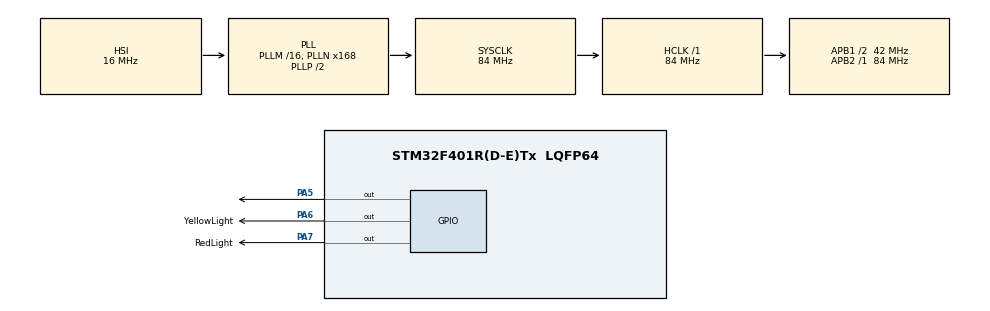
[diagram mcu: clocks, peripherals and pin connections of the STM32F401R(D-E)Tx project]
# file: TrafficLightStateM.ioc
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FREERTOS.Tasks01=vTrafficTask,24,256,StartTrafficTask,Default,NULL,Dynamic,NULL,NULL
Mcu.Family=STM32F4
Mcu.Name=STM32F401R(D-E)Tx
Mcu.Package=LQFP64
NVIC.PriorityGroup=NVIC_PRIORITYGROUP_4
NVIC.TIM5_IRQn=true\:15\:0\:false\:false\:true\:false\:false\:true\:true
NVIC.TimeBase=TIM5_IRQn
NVIC.TimeBaseIP=TIM5
PA5.Signal=GPIO_Output
PA6.GPIO_Label=YellowLight
PA6.Signal=GPIO_Output
PA7.GPIO_Label=RedLight
PA7.Signal=GPIO_Output
ProjectManager.HeapSize=0x200
ProjectManager.StackSize=0x400
ProjectManager.TargetToolchain=STM32CubeIDE
RCC.48MHZClocksFreq_Value=42000000
RCC.AHBFreq_Value=84000000
RCC.APB1CLKDivider=RCC_HCLK_DIV2
RCC.APB1Freq_Value=42000000
RCC.APB1TimFreq_Value=84000000
RCC.APB2Freq_Value=84000000
RCC.APB2TimFreq_Value=84000000
RCC.CortexFreq_Value=84000000
RCC.HCLKFreq_Value=84000000
RCC.HSE_VALUE=25000000
RCC.HSI_VALUE=16000000
RCC.LSE_VALUE=32768
RCC.PLLN=168
RCC.SYSCLKFreq_VALUE=84000000
RCC.SYSCLKSource=RCC_SYSCLKSOURCE_PLLCLK
RCC.VCOOutputFreq_Value=168000000
VP_FREERTOS_VS_CMSIS_V2.Mode=CMSIS_V2
VP_SYS_VS_tim5.Mode=TIM5
board=custom

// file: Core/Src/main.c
/* USER CODE BEGIN Header */
/**
  ******************************************************************************
  * @file           : main.c
  * @brief          : Main program body
  ******************************************************************************
  * @attention
  *
  * Copyright (c) 2026 STMicroelectronics.
  * All rights reserved.
  *
  * This software is licensed under terms that can be found in the LICENSE file
  * in the root directory of this software component.
  * If no LICENSE file comes with this software, it is provided AS-IS.
  *
  ******************************************************************************
  */
/* USER CODE END Header */
#include "main.h"
#include "cmsis_os.h"

/* Definitions for vTrafficTask */
osThreadId_t vTrafficTaskHandle;
const osThreadAttr_t vTrafficTask_attributes = {
  .name = "vTrafficTask",
  .stack_size = 256 * 4,
  .priority = (osPriority_t) osPriorityNormal,
};
/* USER CODE BEGIN PV */
typedef enum
{
	STATE_GREEN,
	STATE_YELLOW,
	STATE_RED
}TrafficState_t;
/* USER CODE END PV */

void SystemClock_Config(void);
static void MX_GPIO_Init(void);
void StartTrafficTask(void *argument);

int main(void)
{

  /* MCU Configuration--------------------------------------------------------*/

  /* Reset of all peripherals, Initializes the Flash interface and the Systick. */
  HAL_Init();

  /* Configure the system clock */
  SystemClock_Config();

  /* Initialize all configured peripherals */
  MX_GPIO_Init();

  /* Init scheduler */
  osKernelInitialize();

  /* Create the thread(s) */
  /* creation of vTrafficTask */
  vTrafficTaskHandle = osThreadNew(StartTrafficTask, NULL, &vTrafficTask_attributes);

  /* Start scheduler */
  osKernelStart();

  /* We should never get here as control is now taken by the scheduler */

  /* Infinite loop */
  while (1)
  {

  }
}

void SystemClock_Config(void)
{
  RCC_OscInitTypeDef RCC_OscInitStruct = {0};
  RCC_ClkInitTypeDef RCC_ClkInitStruct = {0};

  /** Configure the main internal regulator output voltage
  */
  __HAL_RCC_PWR_CLK_ENABLE();
  __HAL_PWR_VOLTAGESCALING_CONFIG(PWR_REGULATOR_VOLTAGE_SCALE2);

  /** Initializes the RCC Oscillators according to the specified parameters
  * in the RCC_OscInitTypeDef structure.
  */
  RCC_OscInitStruct.OscillatorType = RCC_OSCILLATORTYPE_HSI;
  RCC_OscInitStruct.HSIState = RCC_HSI_ON;
  RCC_OscInitStruct.HSICalibrationValue = RCC_HSICALIBRATION_DEFAULT;
  RCC_OscInitStruct.PLL.PLLState = RCC_PLL_ON;
  RCC_OscInitStruct.PLL.PLLSource = RCC_PLLSOURCE_HSI;
  RCC_OscInitStruct.PLL.PLLM = 16;
  RCC_OscInitStruct.PLL.PLLN = 168;
  RCC_OscInitStruct.PLL.PLLP = RCC_PLLP_DIV2;
  RCC_OscInitStruct.PLL.PLLQ = 4;
  if (HAL_RCC_OscConfig(&RCC_OscInitStruct) != HAL_OK)
  {
    Error_Handler();
  }

  /** Initializes the CPU, AHB and APB buses clocks
  */
  RCC_ClkInitStruct.ClockType = RCC_CLOCKTYPE_HCLK|RCC_CLOCKTYPE_SYSCLK
                              |RCC_CLOCKTYPE_PCLK1|RCC_CLOCKTYPE_PCLK2;
  RCC_ClkInitStruct.SYSCLKSource = RCC_SYSCLKSOURCE_PLLCLK;
  RCC_ClkInitStruct.AHBCLKDivider = RCC_SYSCLK_DIV1;
  RCC_ClkInitStruct.APB1CLKDivider = RCC_HCLK_DIV2;
  RCC_ClkInitStruct.APB2CLKDivider = RCC_HCLK_DIV1;

  if (HAL_RCC_ClockConfig(&RCC_ClkInitStruct, FLASH_LATENCY_2) != HAL_OK)
  {
    Error_Handler();
  }
}

static void MX_GPIO_Init(void)
{
  GPIO_InitTypeDef GPIO_InitStruct = {0};

  /* GPIO Ports Clock Enable */
  __HAL_RCC_GPIOA_CLK_ENABLE();

  /*Configure GPIO pin Output Level */
  HAL_GPIO_WritePin(GPIOA, GPIO_PIN_5|YellowLight_Pin|RedLight_Pin, GPIO_PIN_RESET);

  /*Configure GPIO pins : PA5 YellowLight_Pin RedLight_Pin */
  GPIO_InitStruct.Pin = GPIO_PIN_5|YellowLight_Pin|RedLight_Pin;
  GPIO_InitStruct.Mode = GPIO_MODE_OUTPUT_PP;
  GPIO_InitStruct.Pull = GPIO_NOPULL;
  GPIO_InitStruct.Speed = GPIO_SPEED_FREQ_LOW;
  HAL_GPIO_Init(GPIOA, &GPIO_InitStruct);

}

void StartTrafficTask(void *argument)
{
  /* USER CODE BEGIN 5 */
	TrafficState_t currentState = STATE_GREEN;
	//TickType_t startTick;
  /* Infinite loop */
  for(;;)
  {
    //osDelay(1);
	  //startTick = xTaskGetTickCount();
	  switch(currentState)
	  {
	  case STATE_GREEN:
		  HAL_GPIO_WritePin(GPIOA, GPIO_PIN_5, GPIO_PIN_SET);
		  HAL_GPIO_WritePin(GPIOA, GPIO_PIN_6, GPIO_PIN_RESET);
		  HAL_GPIO_WritePin(GPIOA, GPIO_PIN_7, GPIO_PIN_RESET);
		  vTaskDelay(3000);
		  currentState = STATE_YELLOW;
		  break;
	  case STATE_YELLOW:
		  HAL_GPIO_WritePin(GPIOA, GPIO_PIN_5, GPIO_PIN_RESET);
		  HAL_GPIO_WritePin(GPIOA, GPIO_PIN_7, GPIO_PIN_RESET);
		  for(int i=0;i<5;i++){
			  HAL_GPIO_WritePin(GPIOA, GPIO_PIN_6, GPIO_PIN_SET);
			  vTaskDelay(100);
			  HAL_GPIO_WritePin(GPIOA, GPIO_PIN_6, GPIO_PIN_RESET);
			  vTaskDelay(100);
		  }
		  currentState = STATE_RED;
		  break;
	  case STATE_RED:
		  HAL_GPIO_WritePin(GPIOA, GPIO_PIN_6, GPIO_PIN_RESET);
		  HAL_GPIO_WritePin(GPIOA, GPIO_PIN_5, GPIO_PIN_RESET);
		  HAL_GPIO_WritePin(GPIOA, GPIO_PIN_7, GPIO_PIN_SET);
		  vTaskDelay(3000);
		  currentState = STATE_GREEN;
		  break;
	  default:
		  currentState = STATE_GREEN;
		  break;

	  }
	  //HAL_GPIO_TogglePin(GPIOA, RedLight_Pin);
	  //vTaskDelay(500);
  }
  /* USER CODE END 5 */
}

void HAL_TIM_PeriodElapsedCallback(TIM_HandleTypeDef *htim)
{
  if (htim->Instance == TIM5)
  {
    HAL_IncTick();
  }
}

void Error_Handler(void)
{
  __disable_irq();
  while (1)
  {
  }
}
